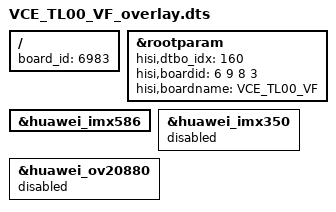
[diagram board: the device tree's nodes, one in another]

/**
 * Copyright (C) 2014 Hisilicon Ltd.
 *
 *  This program is free software; you can redistribute it and/or modify
 *  it under the terms of the GNU General Public License version 2 as
 *  publishhed by the Free Software Foundation.
 */

/dts-v1/;
/plugin/;
/include/ "VCE_TL00_VE_overlay.dtsi"

/ {
	board_id = <6983>;
};
&rootparam {
        hisi,dtbo_idx = <160>;
    hisi,boardid = <6 9 8 3>;
    hisi,boardname = "VCE_TL00_VF";
};

&huawei_imx586 {
	status = "ok";
};

&huawei_imx350 {
	status = "disable";
};

&huawei_ov20880 {
	status = "disable";
};

